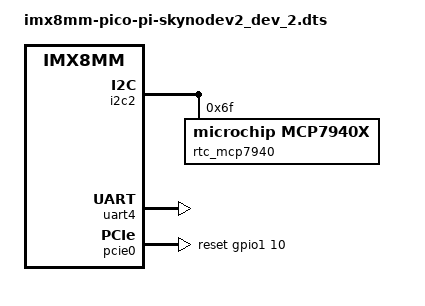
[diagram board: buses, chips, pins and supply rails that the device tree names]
/*
 * Copyright 2020 Auterion AG
 *
 * Author: Helge Bahmann <helge@auterion.com>
 *
 * This program is free software; you can redistribute it and/or
 * modify it under the terms of the GNU General Public License
 * as published by the Free Software Foundation; either version 2
 * of the License, or (at your option) any later version.
 *
 * This program is distributed in the hope that it will be useful,
 * but WITHOUT ANY WARRANTY; without even the implied warranty of
 * MERCHANTABILITY or FITNESS FOR A PARTICULAR PURPOSE.  See the
 * GNU General Public License for more details.
 */

/* This defines the features of the second Skynode boards: production batch
 * with connectors swapped but fixed with an adapter board to make PCIe
 * accessible. */

/dts-v1/;

#include "imx8mm-pico-pi.dts"

/*
 * Real Time Clock
 *
 * We do not use the realtime clock integrated into i.MX8MM security controller,
 * but have one connected via i2c bus.
 */

/delete-node/ &snvs_rtc;

&i2c2 {
	rtc_mcp7940: mcp7940 {
		compatible = "microchip,mcp7940x";
		reg = <0x6f>;
	};
};

/*
 * UART
 *
 * Flight controller is attached to UART4, using pins normally used for
 * SPI2 or other purposes (mipi csi controls). This activates UART4 and
 * maps pins for use by flight controller.
 */

/* Delete pinctrls with conflicting mappings for ECSPI2_{SCLK|MOSI} */
/delete-node/ &pinctrl_tfa98xx;
/delete-node/ &pinctrl_csi_pwn;

/* The pins used by UART4 are multiplexed with MIPI control which thus also
 * becomes unavailable. */
/delete-node/ &ov5645_mipi;
/delete-node/ &mipi_csi_1;
/delete-node/ &csi1_bridge;

&iomuxc {
	/* Map UART4 to ECSPI2 pads. */
	imx8mm-pico {
		pinctrl_uart4: uart4grp {
			fsl,pins = <
				MX8MM_IOMUXC_ECSPI2_SCLK_UART4_DCE_RX	0x140
				MX8MM_IOMUXC_ECSPI2_MOSI_UART4_DCE_TX	0x140
				// Remap 'normal' uart pads so they do not accidentally pull
				// line low in case they are connected to something.
				MX8MM_IOMUXC_UART4_RXD_GPIO5_IO28	0x19
				MX8MM_IOMUXC_UART4_TXD_GPIO5_IO29	0x19
			>;
		};
	};
};

/* Activate UART and link it to pinctrl. */
&uart4 {
	pinctrl-names = "default";
	pinctrl-0 = <&pinctrl_uart4>;
	status = "okay";
};

/*
 * PCI Express
 *
 * Single PCIe link connecting to EHCI host controller. Using internal
 * oscillator as reference clock.
 */
&iomuxc {
	imx8mm-pico {
		pinctrl_pcie0: pcie0grp {
			fsl,pins = <
				MX8MM_IOMUXC_I2C4_SCL_PCIE1_CLKREQ_B	0x61 /* open drain, pull up */
				MX8MM_IOMUXC_GPIO1_IO05_GPIO1_IO5	0x41
				MX8MM_IOMUXC_SAI2_RXFS_GPIO4_IO21	0x41
			>;
		};
	};
};

/{
    /delete-node/ backlight_mipi;
};
/delete-node/ &reg_backlight_pwr;

&pcie0 {
	pinctrl-names = "default";
	pinctrl-0 = <&pinctrl_pcie0>;
	disable-gpio = <&gpio1 5 GPIO_ACTIVE_LOW>;
	reset-gpio = <&gpio1 10 GPIO_ACTIVE_HIGH>;
	power-on-gpio = <&gpio3 8 GPIO_ACTIVE_HIGH>;
	clkreq-gpio = <&gpio5 20 GPIO_ACTIVE_LOW>;
	ext_osc = <0>;
	status = "okay";
};

/*
 * LTE Modem
 *
 * The pins used in baseline for tusb320 are required for LTE usb reset
 * sequence. Delete the declaration getting in the way.
 */
/delete-node/ &typec_tusb320;
&usbotg1 {
	/delete-property/ extcon;
};
